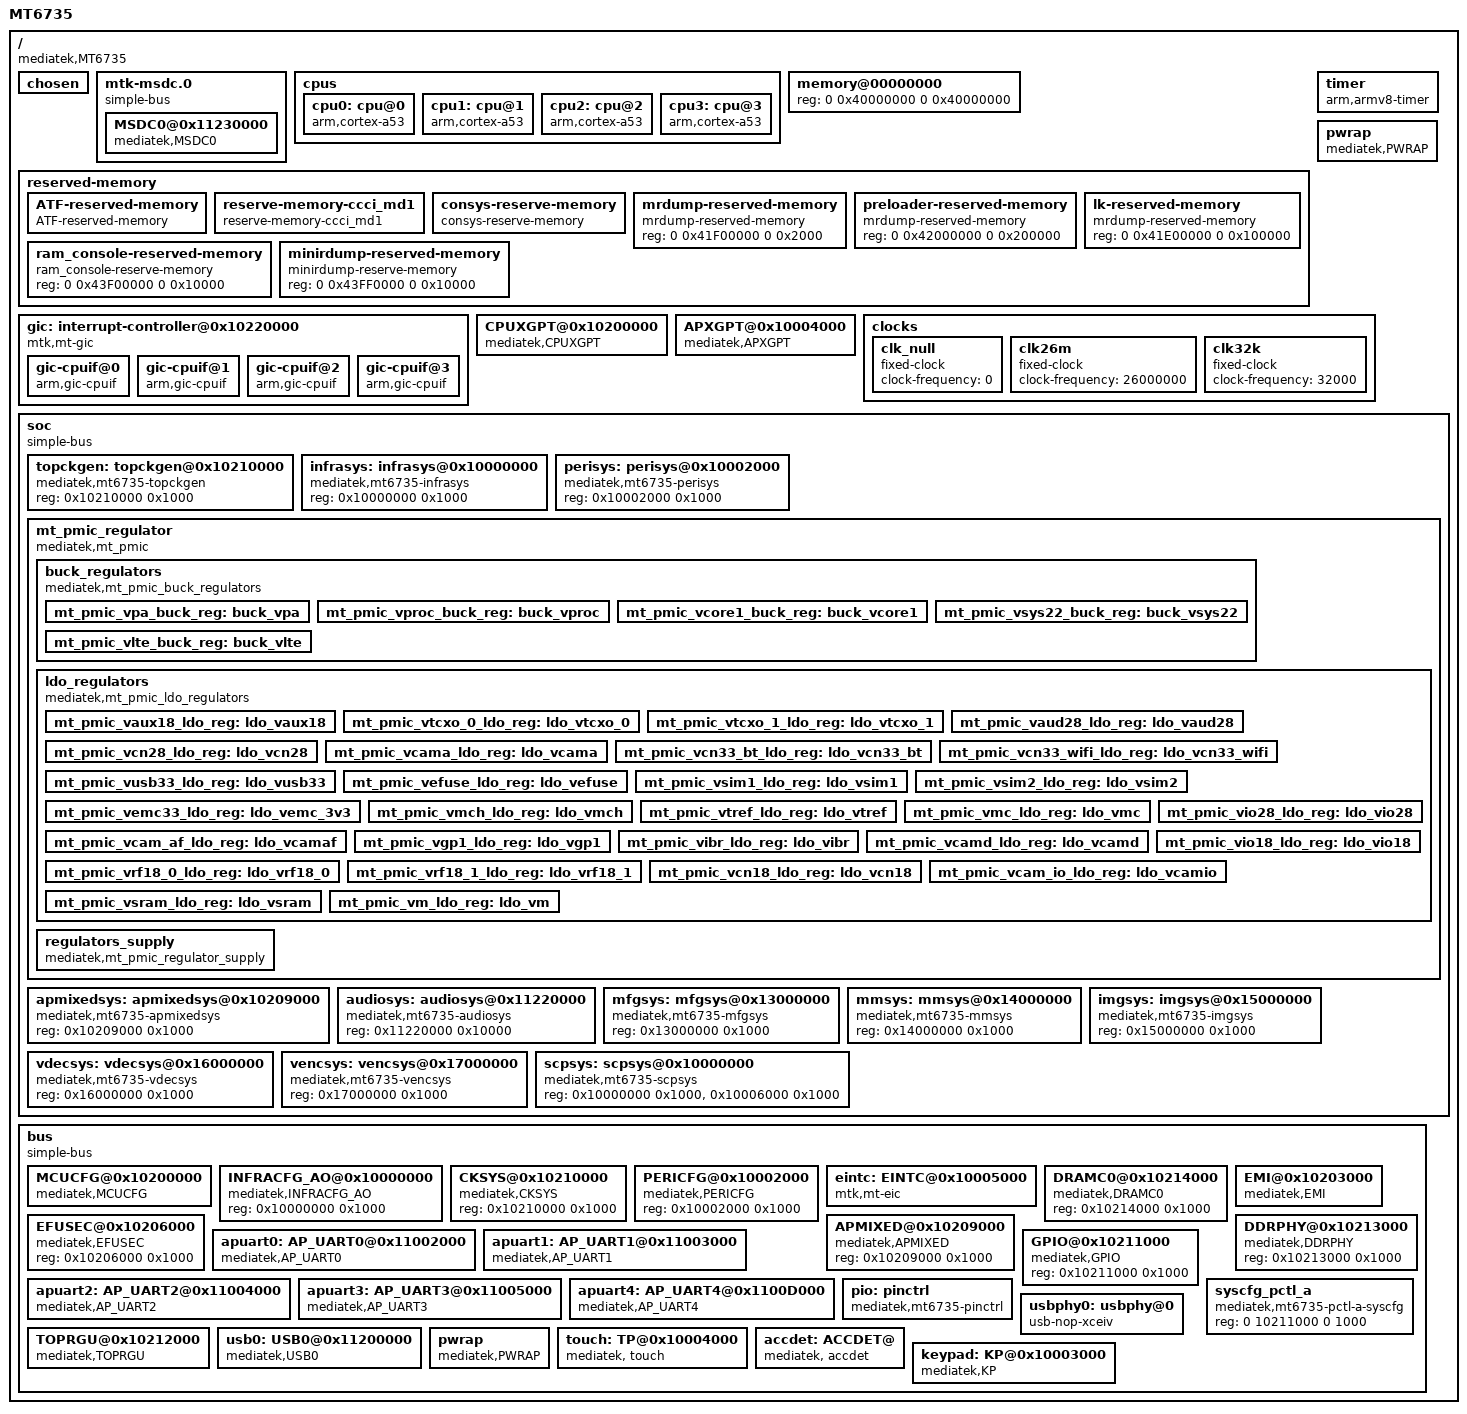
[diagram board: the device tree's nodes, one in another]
/*
 * Mediatek's MT6735 SoC device tree source
 *
 * Copyright (c) 2013 MediaTek Co., Ltd.
 *              http://www.mediatek.com
 *
 */

#include <dt-bindings/clock/mt6735-clk.h>
#include "mt6735-pinfunc.h"

/ {
	model = "MT6735";
	compatible = "mediatek,MT6735";
	interrupt-parent = <&gic>;
	#address-cells = <2>;
	#size-cells = <2>;

	/* chosen */
	chosen {
		bootargs = "console=tty0 console=ttyMT0,921600n1 root=/dev/ram \
initrd=0x44000000,0x300000 loglevel=8 androidboot.hardware=mt6735";
	};

	/* Do not put any bus before mtk-msdc, because it should be mtk-msdc.0 for partition device node usage */
	/*workaround for .0*/
	mtk-msdc.0 {
		compatible = "simple-bus";
		#address-cells = <1>;
		#size-cells = <1>;
		ranges = <0 0 0 0xffffffff>;

		MSDC0@0x11230000 {
			compatible = "mediatek,MSDC0";
			reg = <0x11230000 0x10000  /* MSDC0_BASE   */
			       0x10000E84 0x2>;    /* FPGA PWR_GPIO, PWR_GPIO_EO */
			interrupts = <0 79 0x8>;
		};
	};

	cpus {	#address-cells = <1>;
		#size-cells = <0>;

		cpu0: cpu@0 {
			device_type = "cpu";
			compatible = "arm,cortex-a53";
			reg = <0x000>;
			enable-method = "spin-table";
			cpu-release-addr = <0x0 0x40000200>;
			clock-frequency = <1300000000>;
		};

		cpu1: cpu@1 {
			device_type = "cpu";
			compatible = "arm,cortex-a53";
			reg = <0x001>;
			enable-method = "spin-table";
			cpu-release-addr = <0x0 0x40000200>;
			clock-frequency = <1300000000>;
		};

		cpu2: cpu@2 {
			device_type = "cpu";
			compatible = "arm,cortex-a53";
			reg = <0x002>;
			enable-method = "spin-table";
			cpu-release-addr = <0x0 0x40000200>;
			clock-frequency = <1300000000>;
		};

		cpu3: cpu@3 {
			device_type = "cpu";
			compatible = "arm,cortex-a53";
			reg = <0x003>;
			enable-method = "spin-table";
			cpu-release-addr = <0x0 0x40000200>;
			clock-frequency = <1300000000>;
		};
/*
		cpu4: cpu@4 {
			device_type = "cpu";
			compatible = "arm,cortex-a53";
			reg = <0x100>;
			enable-method = "spin-table";
			cpu-release-addr = <0x0 0x40000200>;
			clock-frequency = <2000000000>;
		};

		cpu5: cpu@5 {
			device_type = "cpu";
			compatible = "arm,cortex-a53";
			reg = <0x101>;
			enable-method = "spin-table";
			cpu-release-addr = <0x0 0x40000200>;
			clock-frequency = <2000000000>;
		};

		cpu6: cpu@6 {
			device_type = "cpu";
			compatible = "arm,cortex-a53";
			reg = <0x102>;
			enable-method = "spin-table";
			cpu-release-addr = <0x0 0x40000200>;
			clock-frequency = <2000000000>;
		};

		cpu7: cpu@7 {
			device_type = "cpu";
			compatible = "arm,cortex-a53";
			reg = <0x103>;
			enable-method = "spin-table";
			cpu-release-addr = <0x0 0x40000200>;
			clock-frequency = <2000000000>;

		};
*/
	};

	memory@00000000 {
		device_type = "memory";
		reg = <0 0x40000000 0 0x40000000>;
	};

	reserved-memory {
		#address-cells = <2>;
		#size-cells = <2>;
		ranges;

		/* reserve 192KB at DRAM start + 48MB */
		ATF-reserved-memory {
			compatible = "ATF-reserved-memory";
			no-map;
			reg = <0 0x43000000 0 0x30000>;
		};

		reserve-memory-ccci_md1 {
			compatible = "reserve-memory-ccci_md1";
			no-map;
			size = <0 0x3810000>; // md_size+smem_size
			alignment = <0 0x2000000>;
			alloc-ranges = <0 0x40000000 0 0xC0000000>;
		};

		consys-reserve-memory {
			compatible = "consys-reserve-memory";
			no-map;
			size = <0 0x200000>;
			alignment = <0 0x200000>;
		};

		mrdump-reserved-memory {
			compatible = "mrdump-reserved-memory";
			reg = <0 0x41F00000 0 0x2000>;
		};

		preloader-reserved-memory {
			compatible = "mrdump-reserved-memory";
			reg = <0 0x42000000 0 0x200000>;
		};

		lk-reserved-memory {
			compatible = "mrdump-reserved-memory";
			reg = <0 0x41E00000 0 0x100000>;
		};


		/*
		reserve-memory-test {
			compatible = "reserve-memory-test";
			no-map;
			size = <0 0x4000000>;
			alignment = <0 0x2000000>;
		};

		mrdump-reserved-memory {
			compatible = "mrdump";
			reg = <0 0x80000000 0 0x4000000>;
		};
		*/
		ram_console-reserved-memory {
			compatible = "ram_console-reserve-memory";
			reg = <0 0x43F00000 0 0x10000>;
		};

		minirdump-reserved-memory {
			compatible = "minirdump-reserve-memory";
			reg = <0 0x43FF0000 0 0x10000>;
		};
	};

	gic: interrupt-controller@0x10220000 {
		compatible = "mtk,mt-gic";
		#interrupt-cells = <3>;
		#address-cells = <0>;
		interrupt-controller;
		reg = <0 0x10221000 0 0x1000>,
			<0 0x10222000 0 0x1000>,
			<0 0x10200620 0 0x1000>;
		interrupts = <1 9 0xf04>;

		gic-cpuif@0 {
			compatible = "arm,gic-cpuif";
			cpuif-id = <0>;
			cpu = <&cpu0>;
		};

		gic-cpuif@1 {
			compatible = "arm,gic-cpuif";
			cpuif-id = <1>;
			cpu = <&cpu1>;
		};

		gic-cpuif@2 {
			compatible = "arm,gic-cpuif";
			cpuif-id = <2>;
			cpu = <&cpu2>;
		};

		gic-cpuif@3 {
			compatible = "arm,gic-cpuif";
			cpuif-id = <3>;
			cpu = <&cpu3>;
		};


	};

	CPUXGPT@0x10200000 {
		compatible = "mediatek,CPUXGPT";
		reg = <0 0x10200000 0 0x1000>;
		interrupts = <0 64 0x4>,
				<0 65 0x4>,
				<0 66 0x4>,
				<0 67 0x4>,
				<0 68 0x4>,
				<0 69 0x4>,
				<0 70 0x4>,
				<0 71 0x4>;
	};

	APXGPT@0x10004000 {
		compatible = "mediatek,APXGPT";
		reg = <0 0x10004000 0 0x1000>;
		interrupts = <0 152 0x8>;
		clock-frequency = <13000000>;
	};

	timer {
	compatible = "arm,armv8-timer";
	interrupts = <1 13 0x8>, /*Secure Physical Timer Event*/
		<1 14 0x8>, /*Non-Secure Physical Timer Event*/
		<1 11 0x8>, /*Virtual Timer Event*/
		<1 10 0x8>; /*Hypervisor Timer Event*/
	clock-frequency = <13000000>;
	};

	pwrap {
			compatible = "mediatek,PWRAP";
			reg = <10001000 1000>;
			interrupts = <0 163 0x4>;
	};

	clocks {
		clk_null: clk_null {
			compatible = "fixed-clock";
			#clock-cells = <0>;
			clock-frequency = <0>;
		};

		clk26m: clk26m {
			compatible = "fixed-clock";
			#clock-cells = <0>;
			clock-frequency = <26000000>;
		};

		clk32k: clk32k {
			compatible = "fixed-clock";
			#clock-cells = <0>;
			clock-frequency = <32000>;
		};
	};

	soc {
		compatible = "simple-bus";
		#address-cells = <1>;
		#size-cells = <1>;
		ranges;

		topckgen: topckgen@0x10210000 {
			compatible = "mediatek,mt6735-topckgen";
			reg = <0x10210000 0x1000>;
			#clock-cells = <1>;
		};

		infrasys: infrasys@0x10000000 {
			compatible = "mediatek,mt6735-infrasys";
			reg = <0x10000000 0x1000>;
			#clock-cells = <1>;
		};

		perisys: perisys@0x10002000 {
			compatible = "mediatek,mt6735-perisys";
			reg = <0x10002000 0x1000>;
			#clock-cells = <1>;
		};
		mt_pmic_regulator {
			compatible = "mediatek,mt_pmic";
			/*reg = <0x01>*/
			buck_regulators {
			compatible = "mediatek,mt_pmic_buck_regulators";
				mt_pmic_vpa_buck_reg: buck_vpa {
					regulator-name = "vpa";
					regulator-min-microvolt = <500000>;
					regulator-max-microvolt = <3650000>;
					regulator-ramp-delay = <50000>;
					regulator-enable-ramp-delay = <180>;
				};
				mt_pmic_vproc_buck_reg: buck_vproc {
					regulator-name = "vproc";
					regulator-min-microvolt = <600000>;
					regulator-max-microvolt = <1393750>;
					regulator-ramp-delay = <6250>;
					regulator-enable-ramp-delay = <180>;
					regulator-always-on;
					regulator-boot-on;
				};
				mt_pmic_vcore1_buck_reg: buck_vcore1 {
					regulator-name = "vcore1";
					regulator-min-microvolt = <600000>;
					regulator-max-microvolt = <1393750>;
					regulator-ramp-delay = <6250>;
					regulator-enable-ramp-delay = <180>;
					regulator-always-on;
					regulator-boot-on;
				};
				mt_pmic_vsys22_buck_reg: buck_vsys22 {
					regulator-name = "vsys22";
					regulator-min-microvolt = <1200000>;
					regulator-max-microvolt = <1993750>;
					regulator-ramp-delay = <6250>;
					regulator-enable-ramp-delay = <180>;
					regulator-always-on;
					regulator-boot-on;
				};
				mt_pmic_vlte_buck_reg: buck_vlte {
					regulator-name = "vlte";
					regulator-min-microvolt = <600000>;
					regulator-max-microvolt = <1393750>;
					regulator-ramp-delay = <6250>;
					regulator-enable-ramp-delay = <180>;
					regulator-always-on;
					regulator-boot-on;
				};
			};	/* End of buck_regulators */
			ldo_regulators {
				compatible = "mediatek,mt_pmic_ldo_regulators";
				mt_pmic_vaux18_ldo_reg: ldo_vaux18 {
					regulator-name = "vaux18";
					regulator-min-microvolt = <1800000>;
					regulator-max-microvolt = <1800000>;
					regulator-enable-ramp-delay = <264>;
					regulator-boot-on;
				};
				mt_pmic_vtcxo_0_ldo_reg: ldo_vtcxo_0 {
					regulator-name = "vtcxo_0";
					regulator-min-microvolt = <2800000>;
					regulator-max-microvolt = <2800000>;
					regulator-enable-ramp-delay = <110>;
					regulator-boot-on;
				};
				mt_pmic_vtcxo_1_ldo_reg: ldo_vtcxo_1 {
					regulator-name = "vtcxo_1";
					regulator-min-microvolt = <2800000>;
					regulator-max-microvolt = <2800000>;
					regulator-enable-ramp-delay = <110>;
				};
				mt_pmic_vaud28_ldo_reg: ldo_vaud28 {
					regulator-name = "vaud28";
					regulator-min-microvolt = <2800000>;
					regulator-max-microvolt = <2800000>;
					regulator-enable-ramp-delay = <264>;
					regulator-boot-on;
				};
				mt_pmic_vcn28_ldo_reg: ldo_vcn28 {
					regulator-name = "vcn28";
					regulator-min-microvolt = <2800000>;
					regulator-max-microvolt = <2800000>;
					regulator-enable-ramp-delay = <264>;
				};
				mt_pmic_vcama_ldo_reg: ldo_vcama {
					regulator-name = "vcama";
					regulator-min-microvolt = <1500000>;
					regulator-max-microvolt = <2800000>;
					regulator-enable-ramp-delay = <264>;
				};
				mt_pmic_vcn33_bt_ldo_reg: ldo_vcn33_bt {
					regulator-name = "vcn33_bt";
					regulator-min-microvolt = <3300000>;
					regulator-max-microvolt = <3600000>;
					regulator-enable-ramp-delay = <264>;
				};
				mt_pmic_vcn33_wifi_ldo_reg: ldo_vcn33_wifi {
					regulator-name = "vcn33_wifi";
					regulator-min-microvolt = <3300000>;
					regulator-max-microvolt = <3600000>;
					regulator-enable-ramp-delay = <264>;
				};
				mt_pmic_vusb33_ldo_reg: ldo_vusb33 {
					regulator-name = "vusb33";
					regulator-min-microvolt = <3300000>;
					regulator-max-microvolt = <3300000>;
					regulator-enable-ramp-delay = <264>;
					regulator-boot-on;
				};
				mt_pmic_vefuse_ldo_reg: ldo_vefuse {
					regulator-name = "vefuse";
					regulator-min-microvolt = <1800000>;
					regulator-max-microvolt = <2200000>;
					regulator-enable-ramp-delay = <264>;
				};
				mt_pmic_vsim1_ldo_reg: ldo_vsim1 {
					regulator-name = "vsim1";
					regulator-min-microvolt = <1700000>;
					regulator-max-microvolt = <2100000>;
					regulator-enable-ramp-delay = <264>;
				};
				mt_pmic_vsim2_ldo_reg: ldo_vsim2 {
					regulator-name = "vsim2";
					regulator-min-microvolt = <1700000>;
					regulator-max-microvolt = <2100000>;
					regulator-enable-ramp-delay = <264>;
				};
				mt_pmic_vemc33_ldo_reg: ldo_vemc_3v3 {
					regulator-name = "vemc_3v3";
					regulator-min-microvolt = <1800000>;
					regulator-max-microvolt = <3300000>;
					regulator-enable-ramp-delay = <264>;
					regulator-boot-on;
				};
				mt_pmic_vmch_ldo_reg: ldo_vmch {
					regulator-name = "vmch";
					regulator-min-microvolt = <2900000>;
					regulator-max-microvolt = <3300000>;
					regulator-enable-ramp-delay = <44>;
					regulator-boot-on;
				};
				mt_pmic_vtref_ldo_reg: ldo_vtref {
					regulator-name = "vtref";
					regulator-min-microvolt = <1800000>;
					regulator-max-microvolt = <1800000>;
					regulator-enable-ramp-delay = <240>;
				};
				mt_pmic_vmc_ldo_reg: ldo_vmc {
					regulator-name = "vmc";
					regulator-min-microvolt = <1800000>;
					regulator-max-microvolt = <3300000>;
					regulator-enable-ramp-delay = <44>;
					regulator-boot-on;
				};
				mt_pmic_vcam_af_ldo_reg: ldo_vcamaf {
					regulator-name = "vcamaf";
					regulator-min-microvolt = <1200000>;
					regulator-max-microvolt = <3300000>;
					regulator-enable-ramp-delay = <264>;
				};
				mt_pmic_vio28_ldo_reg: ldo_vio28 {
					regulator-name = "vio28";
					regulator-min-microvolt = <2800000>;
					regulator-max-microvolt = <2800000>;
					regulator-enable-ramp-delay = <264>;
					regulator-boot-on;
				};
				mt_pmic_vgp1_ldo_reg: ldo_vgp1 {
					regulator-name = "vgp1";
					regulator-min-microvolt = <1200000>;
					regulator-max-microvolt = <3300000>;
					regulator-enable-ramp-delay = <264>;
				};
				mt_pmic_vibr_ldo_reg: ldo_vibr {
					regulator-name = "vibr";
					regulator-min-microvolt = <1200000>;
					regulator-max-microvolt = <3300000>;
					regulator-enable-ramp-delay = <44>;
				};
				mt_pmic_vcamd_ldo_reg: ldo_vcamd {
					regulator-name = "vcamd";
					regulator-min-microvolt = <900000>;
					regulator-max-microvolt = <1500000>;
					regulator-enable-ramp-delay = <264>;
				};
				mt_pmic_vrf18_0_ldo_reg: ldo_vrf18_0 {
					regulator-name = "vrf18_0";
					regulator-min-microvolt = <1825000>;
					regulator-max-microvolt = <1825000>;
					regulator-enable-ramp-delay = <220>;
				};
				mt_pmic_vrf18_1_ldo_reg: ldo_vrf18_1 {
					regulator-name = "vrf18_1";
					regulator-min-microvolt = <1200000>;
					regulator-max-microvolt = <1825000>;
					regulator-enable-ramp-delay = <220>;
				};
				mt_pmic_vio18_ldo_reg: ldo_vio18 {
					regulator-name = "vio18";
					regulator-min-microvolt = <1800000>;
					regulator-max-microvolt = <1800000>;
					regulator-enable-ramp-delay = <264>;
					regulator-boot-on;
				};
				mt_pmic_vcn18_ldo_reg: ldo_vcn18 {
					regulator-name = "vcn18";
					regulator-min-microvolt = <1800000>;
					regulator-max-microvolt = <1800000>;
					regulator-enable-ramp-delay = <44>;
				};
				mt_pmic_vcam_io_ldo_reg: ldo_vcamio {
					regulator-name = "vcamio";
					regulator-min-microvolt = <1200000>;
					regulator-max-microvolt = <1800000>;
					regulator-enable-ramp-delay = <220>;
				};
				mt_pmic_vsram_ldo_reg: ldo_vsram {
					regulator-name = "vsram";
					regulator-min-microvolt = <700000>;
					regulator-max-microvolt = <1493750>;
					regulator-enable-ramp-delay = <220>;
					regulator-ramp-delay = <6250>;
					regulator-boot-on;
				};
				mt_pmic_vm_ldo_reg: ldo_vm {
					regulator-name = "vm";
					regulator-min-microvolt = <1240000>;
					regulator-max-microvolt = <1540000>;
					regulator-enable-ramp-delay = <264>;
					regulator-boot-on;
				};
			};/* End of ldo_regulators */
			regulators_supply {
				compatible = "mediatek,mt_pmic_regulator_supply";
				VAUX18-supply = <&mt_pmic_vaux18_ldo_reg>;
				VTCXO_0-supply = <&mt_pmic_vtcxo_0_ldo_reg>;
				VTCXO_1-supply = <&mt_pmic_vtcxo_1_ldo_reg>;
				VAUD28-supply = <&mt_pmic_vaud28_ldo_reg>;
				VEFUSE-supply = <&mt_pmic_vefuse_ldo_reg>;
				VSIM1-supply = <&mt_pmic_vsim1_ldo_reg>;
				VSIM2-supply = <&mt_pmic_vsim2_ldo_reg>;
				VEMC_3V3-supply = <&mt_pmic_vemc33_ldo_reg>;
				VMCH-supply = <&mt_pmic_vmch_ldo_reg>;
				VTREF-supply = <&mt_pmic_vtref_ldo_reg>;
				VMC-supply = <&mt_pmic_vmc_ldo_reg>;
				VIO28-supply = <&mt_pmic_vio28_ldo_reg>;
				VIBR-supply = <&mt_pmic_vibr_ldo_reg>;
				VRF18_0-supply = <&mt_pmic_vrf18_0_ldo_reg>;
				VRF18_1-supply = <&mt_pmic_vrf18_1_ldo_reg>;
				VIO18-supply = <&mt_pmic_vio18_ldo_reg>;
				VSRAM-supply = <&mt_pmic_vsram_ldo_reg>;
				VM-supply = <&mt_pmic_vm_ldo_reg>;
			};/* End of regulators_supply */
		};/* End of mt_pmic_regulator */

		apmixedsys: apmixedsys@0x10209000 {
			compatible = "mediatek,mt6735-apmixedsys";
			reg = <0x10209000 0x1000>;
			#clock-cells = <1>;
		};

		audiosys: audiosys@0x11220000 {
			compatible = "mediatek,mt6735-audiosys";
			reg = <0x11220000 0x10000>;
			#clock-cells = <1>;
		};

		mfgsys: mfgsys@0x13000000 {
			compatible = "mediatek,mt6735-mfgsys";
			reg = <0x13000000 0x1000>;
			#clock-cells = <1>;
		};

		mmsys: mmsys@0x14000000 {
			compatible = "mediatek,mt6735-mmsys";
			reg = <0x14000000 0x1000>;
			#clock-cells = <1>;
		};

		imgsys: imgsys@0x15000000 {
			compatible = "mediatek,mt6735-imgsys";
			reg = <0x15000000 0x1000>;
			#clock-cells = <1>;
		};

		vdecsys: vdecsys@0x16000000 {
			compatible = "mediatek,mt6735-vdecsys";
			reg = <0x16000000 0x1000>;
			#clock-cells = <1>;
		};

		vencsys: vencsys@0x17000000 {
			compatible = "mediatek,mt6735-vencsys";
			reg = <0x17000000 0x1000>;
			#clock-cells = <1>;
		};

		scpsys: scpsys@0x10000000 {
			compatible = "mediatek,mt6735-scpsys";
			reg = <0x10000000 0x1000>, <0x10006000 0x1000>;
			#clock-cells = <1>;
		};
	};

	bus {
		compatible = "simple-bus";
		#address-cells = <1>;
		#size-cells = <1>;
		ranges = <0 0 0 0xffffffff>;

		MCUCFG@0x10200000 {
			compatible = "mediatek,MCUCFG";
			reg = <0x10200000 0x200>;
			interrupts = <0 71 0x4>;
		};

		INFRACFG_AO@0x10000000 {
			compatible = "mediatek,INFRACFG_AO";
			reg = <0x10000000 0x1000>;
		};

		CKSYS@0x10210000 {
			compatible = "mediatek,CKSYS";
			reg = <0x10210000 0x1000>;
		};

		PERICFG@0x10002000 {
			compatible = "mediatek,PERICFG";
			reg = <0x10002000 0x1000>;
		};

		eintc: EINTC@0x10005000 {
			compatible = "mtk,mt-eic";
			reg = <0x10005000 0x1000>;
			interrupts = <0 153 0x4>;

			#interrupt-cells = <2>;
			interrupt-controller;

			max_eint_num = <213>;
			mapping_table_entry = <0>;
		};

		DRAMC0@0x10214000 {
			compatible = "mediatek,DRAMC0";
			reg = <0x10214000 0x1000>;
		};

		EMI@0x10203000 {
			compatible = "mediatek,EMI";
			reg = <0x10203000 0x1000>;
			interrupts = <0 136 0x4>;
		};

		EFUSEC@0x10206000 {
			compatible = "mediatek,EFUSEC";
			reg = <0x10206000 0x1000>;
		};

		APMIXED@0x10209000 {
			compatible = "mediatek,APMIXED";
			reg = <0x10209000 0x1000>;
		};

		DDRPHY@0x10213000 {
			compatible = "mediatek,DDRPHY";
			reg = <0x10213000 0x1000>;
		};

		apuart0: AP_UART0@0x11002000 {
			cell-index = <0>;
			compatible = "mediatek,AP_UART0";
			reg = <0x11002000 0x1000>;
			interrupts = <0 91 0x8>;

			clock-frequency = <26000000>;
			clock-div = <1>;
			clock-names = "uart0-main", "uart-apdma";
		};

		apuart1: AP_UART1@0x11003000 {
			cell-index = <1>;
			compatible = "mediatek,AP_UART1";
			reg = <0x11003000 0x1000>;
			interrupts = <0 92 0x8>;

			clock-frequency = <26000000>;
			clock-div = <1>;
			clock-names = "uart1-main";

		};

		apuart2: AP_UART2@0x11004000 {
			cell-index = <2>;
			compatible = "mediatek,AP_UART2";
			reg = <0x11004000 0x1000>;
			interrupts = <0 93 0x8>;

			clock-frequency = <26000000>;
			clock-div = <1>;
			clock-names = "uart2-main";
		};

		apuart3: AP_UART3@0x11005000 {
			cell-index = <3>;
			compatible = "mediatek,AP_UART3";
			reg = <0x11005000 0x1000>;
			interrupts = <0 94 0x8>;

			clock-frequency = <26000000>;
			clock-div = <1>;
			clock-names = "uart3-main";
		};

		apuart4: AP_UART4@0x1100D000 {
			cell-index = <4>;
			compatible = "mediatek,AP_UART4";
			reg = <0x1100D000 0x1000>;
			interrupts = <0 95 0x8>;

			clock-frequency = <26000000>;
			clock-div = <1>;
			clock-names = "uart4-main";
		};

		GPIO@0x10211000 {
			compatible = "mediatek,GPIO";
			reg = <0x10211000 0x1000>;
		};

		syscfg_pctl_a: syscfg_pctl_a {
			compatible = "mediatek,mt6735-pctl-a-syscfg", "syscon";
			reg = <0 10211000 0 1000>;
		};

		pio: pinctrl {
			compatible = "mediatek,mt6735-pinctrl";
			reg = <0 10211000 0 1000>;
			mediatek,pctl-regmap = <&syscfg_pctl_a>;
			gpio-controller;
			#gpio-cells = <2>;
			interrupt-controller;
			#interrupt-cells = <2>;

		};

		TOPRGU@0x10212000 {
			compatible = "mediatek,TOPRGU";
			reg = <0x10212000 0x1000>;
			interrupts = <0 128 0x2>;
		};

		usb0:USB0@0x11200000 {
			compatible = "mediatek,USB0";
			cell-index = <0>;
			reg = <0x11200000 0x10000>,
				<0x11210000 0x10000>;
			interrupts = <0 72 0x8>;
			mode = <2>;
			multipoint = <1>;
			dyn_fifo = <1>;
			soft_con = <1>;
			dma = <1>;
			num_eps = <16>;
			dma_channels = <8>;
			clock-names = "usb0";
			iddig_gpio = <0 1>;
			drvvbus_gpio = <83 2>;
		};

		usbphy0: usbphy@0 {
			compatible = "usb-nop-xceiv";
		};

		pwrap {
			compatible = "mediatek,PWRAP";
			reg = <0x10001000 0x1000>;
			interrupts = <0 163 0x4>;
		};

		touch: TP@0x10004000 {
			compatible = "mediatek, touch";
			/*VTOUCH-supply = <&mt_pmic_vgp1_ldo_reg>;*/
		};
		accdet: ACCDET@ {
			compatible = "mediatek, accdet";
		};
		keypad: KP@0x10003000 {
			compatible = "mediatek,KP";
			reg = <0x10003000 0x1000>;
			interrupts = <0 164 0x2>;
		};
	};

};
/include/ "cust_kpd.dtsi"
